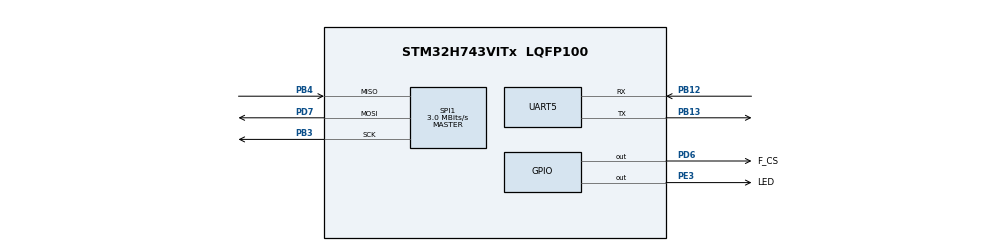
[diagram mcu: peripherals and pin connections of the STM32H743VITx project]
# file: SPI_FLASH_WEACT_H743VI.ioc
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CORTEX_M7.default_mode_Activation=1
Mcu.Family=STM32H7
Mcu.Name=STM32H743VITx
Mcu.Package=LQFP100
NVIC.PriorityGroup=NVIC_PRIORITYGROUP_4
PB12.Mode=Asynchronous
PB12.Signal=UART5_RX
PB13.Mode=Asynchronous
PB13.Signal=UART5_TX
PB3\ (JTDO/TRACESWO).Mode=Full_Duplex_Master
PB3\ (JTDO/TRACESWO).Signal=SPI1_SCK
PB4\ (NJTRST).Mode=Full_Duplex_Master
PB4\ (NJTRST).Signal=SPI1_MISO
PC14-OSC32_IN\ (OSC32_IN).Mode=LSE-External-Oscillator
PC14-OSC32_IN\ (OSC32_IN).Signal=RCC_OSC32_IN
PC15-OSC32_OUT\ (OSC32_OUT).Mode=LSE-External-Oscillator
PC15-OSC32_OUT\ (OSC32_OUT).Signal=RCC_OSC32_OUT
PD6.GPIO_Label=F_CS
PD6.GPIO_Speed=GPIO_SPEED_FREQ_VERY_HIGH
PD6.PinState=GPIO_PIN_SET
PD6.Signal=GPIO_Output
PD7.Mode=Full_Duplex_Master
PD7.Signal=SPI1_MOSI
PE3.GPIO_Label=LED
PE3.Signal=GPIO_Output
PH0-OSC_IN\ (PH0).Mode=HSE-External-Oscillator
PH0-OSC_IN\ (PH0).Signal=RCC_OSC_IN
PH1-OSC_OUT\ (PH1).Mode=HSE-External-Oscillator
PH1-OSC_OUT\ (PH1).Signal=RCC_OSC_OUT
ProjectManager.HeapSize=0x200
ProjectManager.StackSize=0x400
ProjectManager.TargetToolchain=STM32CubeIDE
RCC.ADCFreq_Value=50390625
RCC.APB1Freq_Value=120000000
RCC.APB2Freq_Value=120000000
RCC.APB3Freq_Value=120000000
RCC.APB4Freq_Value=120000000
RCC.CortexFreq_Value=480000000
RCC.D1PPRE=RCC_APB3_DIV2
RCC.D2PPRE1=RCC_APB1_DIV2
RCC.D2PPRE2=RCC_APB2_DIV2
RCC.D3PPRE=RCC_APB4_DIV2
RCC.DIVM1=5
RCC.DIVN1=192
RCC.DIVQ1=20
RCC.HCLKFreq_Value=240000000
RCC.HPRE=RCC_HCLK_DIV2
RCC.PLLFRACN=0
RCC.PLLSourceVirtual=RCC_PLLSOURCE_HSE
RCC.SYSCLKFreq_VALUE=480000000
RCC.SYSCLKSource=RCC_SYSCLKSOURCE_PLLCLK
RCC.USBFreq_Value=48000000
SPI1.BaudRatePrescaler=SPI_BAUDRATEPRESCALER_16
SPI1.CalculateBaudRate=3.0 MBits/s
SPI1.DataSize=SPI_DATASIZE_8BIT
SPI1.Direction=SPI_DIRECTION_2LINES
SPI1.Mode=SPI_MODE_MASTER
SPI1.VirtualType=VM_MASTER
VP_MEMORYMAP_VS_MEMORYMAP.Mode=CurAppReg
board=custom

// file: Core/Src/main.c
/* USER CODE BEGIN Header */
/**
  ******************************************************************************
  * @file           : main.c
  * @brief          : Main program body
  ******************************************************************************
  * @attention
  *
  * Copyright (c) 2026 STMicroelectronics.
  * All rights reserved.
  *
  * This software is licensed under terms that can be found in the LICENSE file
  * in the root directory of this software component.
  * If no LICENSE file comes with this software, it is provided AS-IS.
  *
  ******************************************************************************
  */
/* USER CODE END Header */
#include "main.h"

/* USER CODE BEGIN Includes */
#include <stdio.h>
#include <string.h>
#include "w25qxx.h"

/* USER CODE END Includes */

SPI_HandleTypeDef hspi1;

UART_HandleTypeDef huart5;

void SystemClock_Config(void);
static void MPU_Config(void);
static void MX_GPIO_Init(void);
static void MX_SPI1_Init(void);
static void MX_UART5_Init(void);
/* USER CODE BEGIN PFP */
void W25Qxx_Demo(void);
/* USER CODE END PFP */

int main(void)
{

  /* MPU Configuration--------------------------------------------------------*/
  MPU_Config();

  /* MCU Configuration--------------------------------------------------------*/

  /* Reset of all peripherals, Initializes the Flash interface and the Systick. */
  HAL_Init();

  /* Configure the system clock */
  SystemClock_Config();

  /* Initialize all configured peripherals */
  MX_GPIO_Init();
  MX_SPI1_Init();
  MX_UART5_Init();
  /* USER CODE BEGIN 2 */
  HAL_Delay(100);

  W25Qxx_Demo();
  /* USER CODE END 2 */

  /* Infinite loop */
  while (1)
  {

  }
}

void SystemClock_Config(void)
{
  RCC_OscInitTypeDef RCC_OscInitStruct = {0};
  RCC_ClkInitTypeDef RCC_ClkInitStruct = {0};

  /** Supply configuration update enable
  */
  HAL_PWREx_ConfigSupply(PWR_LDO_SUPPLY);

  /** Configure the main internal regulator output voltage
  */
  __HAL_PWR_VOLTAGESCALING_CONFIG(PWR_REGULATOR_VOLTAGE_SCALE0);

  while(!__HAL_PWR_GET_FLAG(PWR_FLAG_VOSRDY)) {}

  /** Initializes the RCC Oscillators according to the specified parameters
  * in the RCC_OscInitTypeDef structure.
  */
  RCC_OscInitStruct.OscillatorType = RCC_OSCILLATORTYPE_HSE;
  RCC_OscInitStruct.HSEState = RCC_HSE_ON;
  RCC_OscInitStruct.PLL.PLLState = RCC_PLL_ON;
  RCC_OscInitStruct.PLL.PLLSource = RCC_PLLSOURCE_HSE;
  RCC_OscInitStruct.PLL.PLLM = 5;
  RCC_OscInitStruct.PLL.PLLN = 192;
  RCC_OscInitStruct.PLL.PLLP = 2;
  RCC_OscInitStruct.PLL.PLLQ = 20;
  RCC_OscInitStruct.PLL.PLLR = 2;
  RCC_OscInitStruct.PLL.PLLRGE = RCC_PLL1VCIRANGE_2;
  RCC_OscInitStruct.PLL.PLLVCOSEL = RCC_PLL1VCOWIDE;
  RCC_OscInitStruct.PLL.PLLFRACN = 0;
  if (HAL_RCC_OscConfig(&RCC_OscInitStruct) != HAL_OK)
  {
    Error_Handler();
  }

  /** Initializes the CPU, AHB and APB buses clocks
  */
  RCC_ClkInitStruct.ClockType = RCC_CLOCKTYPE_HCLK|RCC_CLOCKTYPE_SYSCLK
                              |RCC_CLOCKTYPE_PCLK1|RCC_CLOCKTYPE_PCLK2
                              |RCC_CLOCKTYPE_D3PCLK1|RCC_CLOCKTYPE_D1PCLK1;
  RCC_ClkInitStruct.SYSCLKSource = RCC_SYSCLKSOURCE_PLLCLK;
  RCC_ClkInitStruct.SYSCLKDivider = RCC_SYSCLK_DIV1;
  RCC_ClkInitStruct.AHBCLKDivider = RCC_HCLK_DIV2;
  RCC_ClkInitStruct.APB3CLKDivider = RCC_APB3_DIV2;
  RCC_ClkInitStruct.APB1CLKDivider = RCC_APB1_DIV2;
  RCC_ClkInitStruct.APB2CLKDivider = RCC_APB2_DIV2;
  RCC_ClkInitStruct.APB4CLKDivider = RCC_APB4_DIV2;

  if (HAL_RCC_ClockConfig(&RCC_ClkInitStruct, FLASH_LATENCY_4) != HAL_OK)
  {
    Error_Handler();
  }
}

static void MX_SPI1_Init(void)
{

  /* SPI1 parameter configuration*/
  hspi1.Instance = SPI1;
  hspi1.Init.Mode = SPI_MODE_MASTER;
  hspi1.Init.Direction = SPI_DIRECTION_2LINES;
  hspi1.Init.DataSize = SPI_DATASIZE_8BIT;
  hspi1.Init.CLKPolarity = SPI_POLARITY_LOW;
  hspi1.Init.CLKPhase = SPI_PHASE_1EDGE;
  hspi1.Init.NSS = SPI_NSS_SOFT;
  hspi1.Init.BaudRatePrescaler = SPI_BAUDRATEPRESCALER_16;
  hspi1.Init.FirstBit = SPI_FIRSTBIT_MSB;
  hspi1.Init.TIMode = SPI_TIMODE_DISABLE;
  hspi1.Init.CRCCalculation = SPI_CRCCALCULATION_DISABLE;
  hspi1.Init.CRCPolynomial = 0x0;
  hspi1.Init.NSSPMode = SPI_NSS_PULSE_ENABLE;
  hspi1.Init.NSSPolarity = SPI_NSS_POLARITY_LOW;
  hspi1.Init.FifoThreshold = SPI_FIFO_THRESHOLD_01DATA;
  hspi1.Init.TxCRCInitializationPattern = SPI_CRC_INITIALIZATION_ALL_ZERO_PATTERN;
  hspi1.Init.RxCRCInitializationPattern = SPI_CRC_INITIALIZATION_ALL_ZERO_PATTERN;
  hspi1.Init.MasterSSIdleness = SPI_MASTER_SS_IDLENESS_00CYCLE;
  hspi1.Init.MasterInterDataIdleness = SPI_MASTER_INTERDATA_IDLENESS_00CYCLE;
  hspi1.Init.MasterReceiverAutoSusp = SPI_MASTER_RX_AUTOSUSP_DISABLE;
  hspi1.Init.MasterKeepIOState = SPI_MASTER_KEEP_IO_STATE_DISABLE;
  hspi1.Init.IOSwap = SPI_IO_SWAP_DISABLE;
  if (HAL_SPI_Init(&hspi1) != HAL_OK)
  {
    Error_Handler();
  }

}

static void MX_UART5_Init(void)
{

  huart5.Instance = UART5;
  huart5.Init.BaudRate = 115200;
  huart5.Init.WordLength = UART_WORDLENGTH_8B;
  huart5.Init.StopBits = UART_STOPBITS_1;
  huart5.Init.Parity = UART_PARITY_NONE;
  huart5.Init.Mode = UART_MODE_TX_RX;
  huart5.Init.HwFlowCtl = UART_HWCONTROL_NONE;
  huart5.Init.OverSampling = UART_OVERSAMPLING_16;
  huart5.Init.OneBitSampling = UART_ONE_BIT_SAMPLE_DISABLE;
  huart5.Init.ClockPrescaler = UART_PRESCALER_DIV1;
  huart5.AdvancedInit.AdvFeatureInit = UART_ADVFEATURE_NO_INIT;
  if (HAL_UART_Init(&huart5) != HAL_OK)
  {
    Error_Handler();
  }
  if (HAL_UARTEx_SetTxFifoThreshold(&huart5, UART_TXFIFO_THRESHOLD_1_8) != HAL_OK)
  {
    Error_Handler();
  }
  if (HAL_UARTEx_SetRxFifoThreshold(&huart5, UART_RXFIFO_THRESHOLD_1_8) != HAL_OK)
  {
    Error_Handler();
  }
  if (HAL_UARTEx_DisableFifoMode(&huart5) != HAL_OK)
  {
    Error_Handler();
  }

}

static void MX_GPIO_Init(void)
{
  GPIO_InitTypeDef GPIO_InitStruct = {0};

  /* GPIO Ports Clock Enable */
  __HAL_RCC_GPIOE_CLK_ENABLE();
  __HAL_RCC_GPIOC_CLK_ENABLE();
  __HAL_RCC_GPIOH_CLK_ENABLE();
  __HAL_RCC_GPIOB_CLK_ENABLE();
  __HAL_RCC_GPIOD_CLK_ENABLE();

  /*Configure GPIO pin Output Level */
  HAL_GPIO_WritePin(LED_GPIO_Port, LED_Pin, GPIO_PIN_RESET);

  /*Configure GPIO pin Output Level */
  HAL_GPIO_WritePin(F_CS_GPIO_Port, F_CS_Pin, GPIO_PIN_SET);

  /*Configure GPIO pin : LED_Pin */
  GPIO_InitStruct.Pin = LED_Pin;
  GPIO_InitStruct.Mode = GPIO_MODE_OUTPUT_PP;
  GPIO_InitStruct.Pull = GPIO_NOPULL;
  GPIO_InitStruct.Speed = GPIO_SPEED_FREQ_LOW;
  HAL_GPIO_Init(LED_GPIO_Port, &GPIO_InitStruct);

  /*Configure GPIO pin : F_CS_Pin */
  GPIO_InitStruct.Pin = F_CS_Pin;
  GPIO_InitStruct.Mode = GPIO_MODE_OUTPUT_PP;
  GPIO_InitStruct.Pull = GPIO_NOPULL;
  GPIO_InitStruct.Speed = GPIO_SPEED_FREQ_VERY_HIGH;
  HAL_GPIO_Init(F_CS_GPIO_Port, &GPIO_InitStruct);

}

 /* MPU Configuration */

void MPU_Config(void)
{
  MPU_Region_InitTypeDef MPU_InitStruct = {0};

  /* Disables the MPU */
  HAL_MPU_Disable();

  /** Initializes and configures the Region and the memory to be protected
  */
  MPU_InitStruct.Enable = MPU_REGION_ENABLE;
  MPU_InitStruct.Number = MPU_REGION_NUMBER0;
  MPU_InitStruct.BaseAddress = 0x0;
  MPU_InitStruct.Size = MPU_REGION_SIZE_4GB;
  MPU_InitStruct.SubRegionDisable = 0x87;
  MPU_InitStruct.TypeExtField = MPU_TEX_LEVEL0;
  MPU_InitStruct.AccessPermission = MPU_REGION_NO_ACCESS;
  MPU_InitStruct.DisableExec = MPU_INSTRUCTION_ACCESS_DISABLE;
  MPU_InitStruct.IsShareable = MPU_ACCESS_SHAREABLE;
  MPU_InitStruct.IsCacheable = MPU_ACCESS_NOT_CACHEABLE;
  MPU_InitStruct.IsBufferable = MPU_ACCESS_NOT_BUFFERABLE;

  HAL_MPU_ConfigRegion(&MPU_InitStruct);
  /* Enables the MPU */
  HAL_MPU_Enable(MPU_PRIVILEGED_DEFAULT);

}

void Error_Handler(void)
{
  __disable_irq();
  while (1)
  {
  }
}
